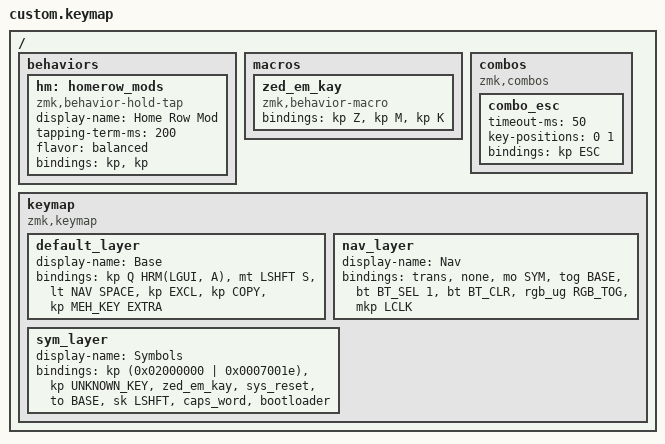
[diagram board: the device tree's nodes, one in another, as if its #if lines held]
/*
 * A deliberately awkward keymap: custom behaviors, function-like macros,
 * conditionals, line continuations and every parameter style.
 */
#include <behaviors.dtsi>
#include <dt-bindings/zmk/keys.h>
#include <dt-bindings/zmk/bt.h>
#include <dt-bindings/zmk/rgb.h>
#include <dt-bindings/zmk/pointing.h>
#include "my-helpers.h"

#define BASE 0
#define NAV  1
#define SYM  2

// Home-row mod shorthand.
#define HRM(mod, key) &hm mod key
#define COPY LC(C)
#define MEH_KEY LC(LS(LA( \
    ESC)))

#ifdef MISSING_FLAG
#define EXTRA &kp F13
#else
#define EXTRA &kp F14
#endif

/ {
    behaviors {
        hm: homerow_mods {
            compatible = "zmk,behavior-hold-tap";
            display-name = "Home Row Mod";
            #binding-cells = <2>;
            tapping-term-ms = <200>;
            flavor = "balanced";
            bindings = <&kp>, <&kp>;
        };
    };

    macros {
        zed_em_kay: zed_em_kay {
            compatible = "zmk,behavior-macro";
            #binding-cells = <0>;
            bindings = <&kp Z &kp M &kp K>;
        };
    };

    combos {
        compatible = "zmk,combos";
        combo_esc {
            timeout-ms = <50>;
            key-positions = <0 1>;
            bindings = <&kp ESC>;
        };
    };

    keymap {
        compatible = "zmk,keymap";

        default_layer {
            display-name = "Base";
            bindings = <
                &kp Q  HRM(LGUI, A)  &mt LSHFT S  &lt NAV SPACE
                &kp EXCL  &kp COPY  &kp MEH_KEY  EXTRA
            >;
        };

        nav_layer {
            display-name = "Nav";
            bindings = <
                &trans  &none  &mo SYM  &tog BASE
                &bt BT_SEL 1  &bt BT_CLR  &rgb_ug RGB_TOG  &mkp LCLK
            >;
        };

        sym_layer {
            display-name = "Symbols";
            bindings = <
                &kp (0x02000000 | 0x0007001e)  &kp UNKNOWN_KEY  &zed_em_kay  &sys_reset
                &to BASE  &sk LSHFT  &caps_word  &bootloader
            >;
        };
    };
};
